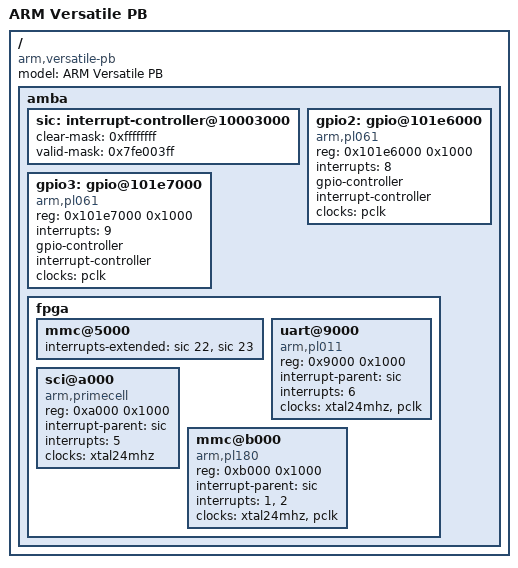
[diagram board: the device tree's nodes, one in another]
#include <versatile-ab.dts>

/ {
	model = "ARM Versatile PB";
	compatible = "arm,versatile-pb";

	amba {
		/* The Versatile PB is using more SIC IRQ lines than the AB */
		sic: interrupt-controller@10003000 {
			clear-mask = <0xffffffff>;
			/*
			 * Valid interrupt lines mask according to
			 * figure 3-30 page 3-74 of ARM DUI 0224B
			 */
			valid-mask = <0x7fe003ff>;
		};

		gpio2: gpio@101e6000 {
			compatible = "arm,pl061", "arm,primecell";
			reg = <0x101e6000 0x1000>;
			interrupts = <8>;
			gpio-controller;
			#gpio-cells = <2>;
			interrupt-controller;
			#interrupt-cells = <2>;
			clocks = <&pclk>;
			clock-names = "apb_pclk";
		};

		gpio3: gpio@101e7000 {
			compatible = "arm,pl061", "arm,primecell";
			reg = <0x101e7000 0x1000>;
			interrupts = <9>;
			gpio-controller;
			#gpio-cells = <2>;
			interrupt-controller;
			#interrupt-cells = <2>;
			clocks = <&pclk>;
			clock-names = "apb_pclk";
		};

		fpga {
			mmc@5000 {
				/*
				 * Overrides the interrupt assignment from
				 * the Versatile AB board file.
				 */
				interrupts-extended = <&sic 22 &sic 23>;
			};
			uart@9000 {
				compatible = "arm,pl011", "arm,primecell";
				reg = <0x9000 0x1000>;
				interrupt-parent = <&sic>;
				interrupts = <6>;
				clocks = <&xtal24mhz>, <&pclk>;
				clock-names = "uartclk", "apb_pclk";
			};
			sci@a000 {
				compatible = "arm,primecell";
				reg = <0xa000 0x1000>;
				interrupt-parent = <&sic>;
				interrupts = <5>;
				clocks = <&xtal24mhz>;
				clock-names = "apb_pclk";
			};
			mmc@b000 {
				compatible = "arm,pl180", "arm,primecell";
				reg = <0xb000 0x1000>;
				interrupt-parent = <&sic>;
				interrupts = <1>, <2>;
				clocks = <&xtal24mhz>, <&pclk>;
				clock-names = "mclk", "apb_pclk";
			};
		};
	};
};
